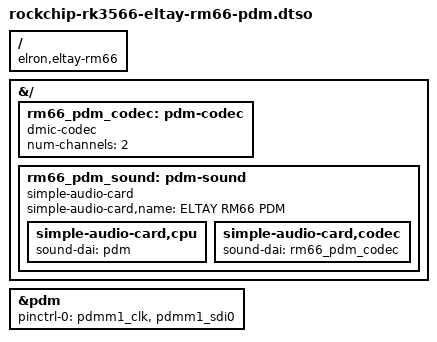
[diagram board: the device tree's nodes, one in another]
// SPDX-License-Identifier: (GPL-2.0+ OR MIT)

/dts-v1/;
/plugin/;

/ {
	compatible = "elron,eltay-rm66", "rockchip,rk3566";
};

&{/} {
	rm66_pdm_codec: pdm-codec {
		compatible = "dmic-codec";
		num-channels = <2>;
		#sound-dai-cells = <0>;
	};

	rm66_pdm_sound: pdm-sound {
		compatible = "simple-audio-card";
		simple-audio-card,name = "ELTAY RM66 PDM";

		simple-audio-card,cpu {
			sound-dai = <&pdm>;
		};

		simple-audio-card,codec {
			sound-dai = <&rm66_pdm_codec>;
		};
	};
};

&pdm {
	pinctrl-names = "default";
	pinctrl-0 = <&pdmm1_clk
		     &pdmm1_sdi0>;
	status = "okay";
};
